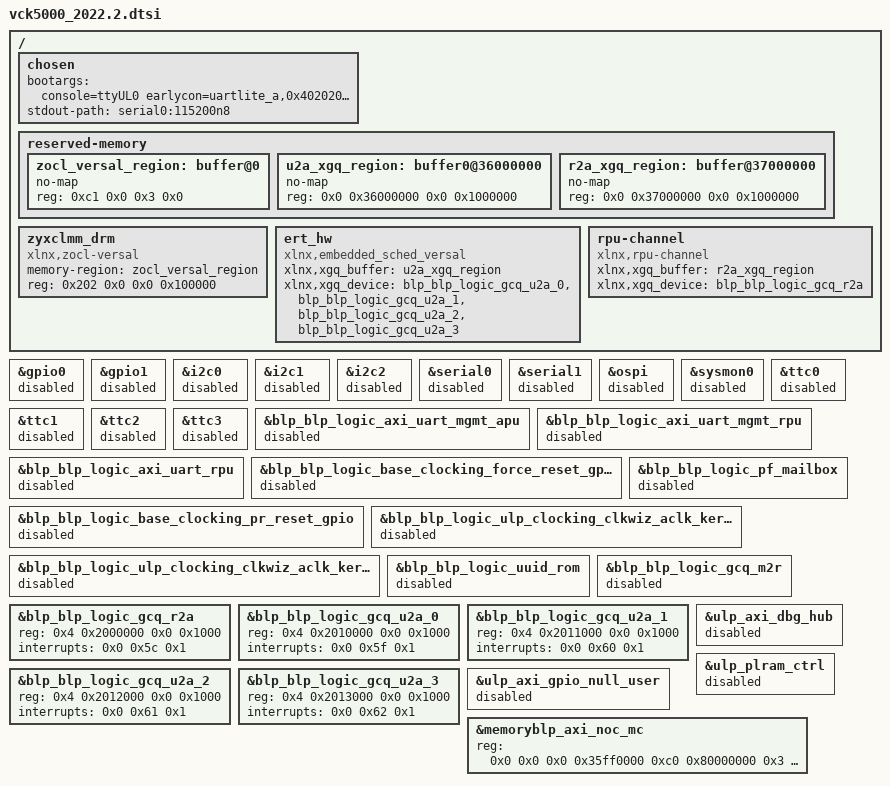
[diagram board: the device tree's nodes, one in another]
&gpio0 {
    status = "disabled";
};
&gpio1 {
    status = "disabled";
};
&i2c0 {
    status = "disabled";
};
&i2c1 {
    status = "disabled";
};
&i2c2 {
    status = "disabled";
};
&serial0 {
    status = "disabled";
};
&serial1 {
    status = "disabled";
};
&ospi {
    status = "disabled";
};
&sysmon0 {
    status = "disabled";
};
&ttc0 {
    status = "disabled";
};
&ttc1 {
    status = "disabled";
};
&ttc2 {
    status = "disabled";
};
&ttc3 {
    status = "disabled";
};
&blp_blp_logic_axi_uart_mgmt_apu {
    status = "disabled";
};
&blp_blp_logic_axi_uart_mgmt_rpu {
    status = "disabled";
};
&blp_blp_logic_axi_uart_rpu {
    status = "disabled";
};
&blp_blp_logic_base_clocking_force_reset_gpio {
    status = "disabled";
};
&blp_blp_logic_base_clocking_pr_reset_gpio {
    status = "disabled";
};
&blp_blp_logic_pf_mailbox {
    status = "disabled";
};
&blp_blp_logic_ulp_clocking_clkwiz_aclk_kernel_00 {
    status = "disabled";
};
&blp_blp_logic_ulp_clocking_clkwiz_aclk_kernel_01 {
    status = "disabled";
};
&blp_blp_logic_uuid_rom {
    status = "disabled";
};
&blp_blp_logic_gcq_m2r {
    status = "disabled";
};
&blp_blp_logic_gcq_r2a {
    reg = <0x4 0x2000000 0x0 0x1000>;
    interrupts = <0x0 0x5c 0x1>;
};
&blp_blp_logic_gcq_u2a_0 {
    reg = <0x4 0x2010000 0x0 0x1000>;
    interrupts = <0x0 0x5f 0x1>;
};
&blp_blp_logic_gcq_u2a_1 {
    reg = <0x4 0x2011000 0x0 0x1000>;
    interrupts = <0x0 0x60 0x1>;
};
&blp_blp_logic_gcq_u2a_2 {
    reg = <0x4 0x2012000 0x0 0x1000>;
    interrupts = <0x0 0x61 0x1>;
};
&blp_blp_logic_gcq_u2a_3 {
    reg = <0x4 0x2013000 0x0 0x1000>;
    interrupts = <0x0 0x62 0x1>;
};
&ulp_axi_dbg_hub {
    status = "disabled";
};
&ulp_axi_gpio_null_user {
    status = "disabled";
};
&ulp_plram_ctrl {
    status = "disabled";
};
&memoryblp_axi_noc_mc {
    reg = <0x0 0x0 0x0 0x35ff0000 0xc0 0x80000000 0x3 0x80000000>;
};
/ {
    chosen {
        bootargs = "console=ttyUL0  earlycon=uartlite_a,0x402020000,115200n8 clk_ignore_unused root=/dev/mmcblk0p2 rw rootwait";
        stdout-path = "serial0:115200n8";
    };

    reserved-memory {
        #address-cells = <0x2>;
        #size-cells = <0x2>;
        ranges;

        zocl_versal_region: buffer@0 {
            no-map;
            reg = <0xc1 0x0 0x3 0x0>;
        };

        u2a_xgq_region: buffer0@36000000 {
            no-map;
            reg = <0x0 0x36000000 0x0 0x1000000>;
        };

        r2a_xgq_region: buffer@37000000 {
            no-map;
            reg = <0x0 0x37000000 0x0 0x1000000>;
        };
    };

	zyxclmm_drm {
		compatible = "xlnx,zocl-versal";
		status = "okay";
		memory-region = <&zocl_versal_region>;
		reg = <0x202 0x0 0x0 0x100000>;
	};

	ert_hw {
		compatible = "xlnx,embedded_sched_versal";
		status = "okay";
		xlnx,xgq_buffer = <&u2a_xgq_region>;
		xlnx,xgq_device = <&blp_blp_logic_gcq_u2a_0 &blp_blp_logic_gcq_u2a_1 &blp_blp_logic_gcq_u2a_2 &blp_blp_logic_gcq_u2a_3>;
		interrupt-names = "irq_sq";
	};

	rpu-channel {
		compatible = "xlnx,rpu-channel";
		xlnx,xgq_buffer = <&r2a_xgq_region>;
		xlnx,xgq_device = <&blp_blp_logic_gcq_r2a>;
		interrupt-names = "irq_sq";
	};
};
